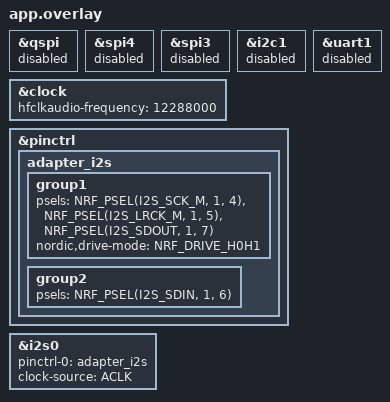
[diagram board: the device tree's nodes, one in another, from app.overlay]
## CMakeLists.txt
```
cmake_minimum_required(VERSION 3.20.0)
find_package(Zephyr REQUIRED HINTS $ENV{ZEPHYR_BASE})
project(openearable_adapter)
target_include_directories(app PRIVATE ../../common src)
target_sources(app PRIVATE src/main.c src/link.c src/pcm.c src/earables.c)
# Build-local hook: do not block Bluetooth RX while awaiting the earable's ATT reply.
set(ATT_SOURCE ${ZEPHYR_BASE}/subsys/bluetooth/host/att.c)
set(ATT_PROXY_SOURCE ${CMAKE_CURRENT_BINARY_DIR}/adapter_att.c)
add_custom_command(OUTPUT ${ATT_PROXY_SOURCE}
    COMMAND ${PYTHON_EXECUTABLE} ${CMAKE_CURRENT_SOURCE_DIR}/cmake/att_hook.py
        ${ATT_SOURCE} ${ATT_PROXY_SOURCE}
    DEPENDS ${ATT_SOURCE} ${CMAKE_CURRENT_SOURCE_DIR}/cmake/att_hook.py
    VERBATIM)
add_custom_target(adapter_att_hook DEPENDS ${ATT_PROXY_SOURCE})
add_dependencies(subsys__bluetooth__host adapter_att_hook)
get_target_property(HOST_SOURCES subsys__bluetooth__host SOURCES)
list(FILTER HOST_SOURCES EXCLUDE REGEX "(^|/)att\\.c$")
set_property(TARGET subsys__bluetooth__host PROPERTY SOURCES ${HOST_SOURCES} ${ATT_PROXY_SOURCE})
target_include_directories(subsys__bluetooth__host PRIVATE ${ZEPHYR_BASE}/subsys/bluetooth/host)
target_sources(app PRIVATE src/proxy.c)
```

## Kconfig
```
# SPDX-License-Identifier: Apache-2.0
mainmenu "OpenEarable adapter"

config ADAPTER_SDC_ISO_CLOCK
    bool
    default y
    select BT_LL_SOFTDEVICE_HEADERS_INCLUDE
    help
      The network core runs SoftDevice Controller. Use its HCI timestamp
      command to align stereo SDUs even though the host runs on the app core.

source "Kconfig.zephyr"
```

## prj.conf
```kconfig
CONFIG_GPIO=y
CONFIG_ADC=y
CONFIG_PINCTRL=y
CONFIG_I2S=y
CONFIG_NRFX_SPIS3=y
CONFIG_FPU=y
CONFIG_FPU_SHARING=y
CONFIG_LIBLC3=y
CONFIG_SPEED_OPTIMIZATIONS=y
CONFIG_MAIN_STACK_SIZE=4096
CONFIG_SYSTEM_WORKQUEUE_STACK_SIZE=4096
CONFIG_HEAP_MEM_POOL_SIZE=32768
# Match Nordic's unicast-client crypto heap: 512 bytes can exhaust during
# CSIP SIRK decryption while another link is pairing or reconnecting.
CONFIG_MBEDTLS_HEAP_SIZE=2048
CONFIG_BT=y
CONFIG_BT_CENTRAL=y
CONFIG_BT_PERIPHERAL=y
CONFIG_BT_MAX_CONN=4
CONFIG_BT_MAX_PAIRED=8
CONFIG_BT_SMP=y
CONFIG_BT_BONDABLE=y
CONFIG_BT_SETTINGS=y
CONFIG_BT_DEVICE_NAME="OpenEarable Adapter"
CONFIG_BT_DEVICE_NAME_DYNAMIC=y
CONFIG_BT_DEVICE_NAME_MAX=64
CONFIG_BT_ID_MAX=3
CONFIG_BT_EXT_ADV=y
CONFIG_BT_EXT_ADV_MAX_ADV_SET=2
CONFIG_BT_GATT_CLIENT=y
CONFIG_BT_GATT_DYNAMIC_DB=y
CONFIG_BT_GATT_AUTO_DISCOVER_CCC=y
# Mirrored CCCs are checked by the proxy for its per-ear host connection.
CONFIG_BT_GATT_ENFORCE_SUBSCRIPTION=n
CONFIG_BT_GATT_AUTO_UPDATE_MTU=y
CONFIG_BT_USER_PHY_UPDATE=y
CONFIG_BT_AUTO_PHY_UPDATE=y
CONFIG_BT_USER_DATA_LEN_UPDATE=y
CONFIG_BT_AUTO_DATA_LEN_UPDATE=y
CONFIG_BT_ATT_TX_COUNT=12
CONFIG_BT_L2CAP_TX_BUF_COUNT=16
CONFIG_BT_CONN_TX_MAX=12
CONFIG_BT_BUF_ACL_TX_COUNT=12
CONFIG_BT_BUF_ACL_RX_COUNT_EXTRA=8
CONFIG_BT_L2CAP_TX_MTU=247
CONFIG_BT_BUF_ACL_RX_SIZE=251
CONFIG_BT_BUF_ACL_TX_SIZE=251
CONFIG_BT_BUF_EVT_RX_SIZE=255
CONFIG_BT_BUF_CMD_TX_SIZE=255
CONFIG_BT_AUDIO=y
CONFIG_BT_ISO_CENTRAL=y
CONFIG_BT_BAP_UNICAST_CLIENT=y
CONFIG_BT_CSIP_SET_COORDINATOR=y
CONFIG_BT_BAP_UNICAST_CLIENT_GROUP_STREAM_COUNT=2
CONFIG_BT_BAP_UNICAST_CLIENT_ASE_SNK_COUNT=2
CONFIG_BT_BAP_UNICAST_CLIENT_ASE_SRC_COUNT=2
CONFIG_BT_ISO_MAX_CHAN=2
CONFIG_BT_ISO_TX_BUF_COUNT=8
CONFIG_BT_ISO_RX_BUF_COUNT=8
CONFIG_BT_ISO_TX_MTU=155
CONFIG_BT_ISO_RX_MTU=155
CONFIG_SETTINGS=y
CONFIG_FLASH=y
CONFIG_FLASH_MAP=y
CONFIG_NVS=y
CONFIG_SETTINGS_NVS=y
CONFIG_LOG=y
CONFIG_LOG_MODE_DEFERRED=y
CONFIG_LOG_BUFFER_SIZE=8192
CONFIG_LOG_BACKEND_UART=n
CONFIG_LOG_BACKEND_RTT=y
CONFIG_USE_SEGGER_RTT=y
CONFIG_RTT_CONSOLE=y
CONFIG_UART_CONSOLE=n
CONFIG_CONSOLE=y
CONFIG_SEGGER_RTT_BUFFER_SIZE_UP=8192
CONFIG_SEGGER_RTT_BUFFER_SIZE_DOWN=256
CONFIG_ASSERT=y
CONFIG_NRF_APPROTECT_USE_UICR=y
```

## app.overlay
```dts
#include <zephyr/dt-bindings/pinctrl/nrf-pinctrl.h>
&qspi { status = "disabled"; };
&spi4 { status = "disabled"; };
&spi3 { status = "disabled"; };
&i2c1 { status = "disabled"; };
&uart1 { status = "disabled"; };
&clock { hfclkaudio-frequency = <12288000>; };
&pinctrl {
    adapter_i2s: adapter_i2s {
        group1 {
            psels = <NRF_PSEL(I2S_SCK_M, 1, 4)>,
                    <NRF_PSEL(I2S_LRCK_M, 1, 5)>,
                    <NRF_PSEL(I2S_SDOUT, 1, 7)>;
            nordic,drive-mode = <NRF_DRIVE_H0H1>;
        };
        group2 {
            psels = <NRF_PSEL(I2S_SDIN, 1, 6)>;
        };
    };
};
&i2s0 {
    status = "okay";
    pinctrl-0 = <&adapter_i2s>;
    pinctrl-names = "default";
    clock-source = "ACLK";
};
```

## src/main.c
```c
/* SPDX-License-Identifier: Apache-2.0 */
#include "adapter.h"
#include <zephyr/drivers/gpio.h>
#include <SEGGER_RTT.h>
#include <zephyr/random/random.h>
#include <hal/nrf_clock.h>
#include <nrfx_clock.h>
atomic_t host_flags, ear_flags, link_errors, pcm_frames, pcm_peak, pairing_token, test_mode,
    reset_epoch;
uint32_t boot_id;
K_MUTEX_DEFINE(name_mutex);
char pair_name[64] = "OpenEarable Adapter";
char pair_hardware_revision[16];
static const struct device *gpio0 = DEVICE_DT_GET(DT_NODELABEL(gpio0));
void adapter_led(unsigned index, bool on) { gpio_pin_set(gpio0, 28 + index, !on); }
int main(void) {
    /* Four LC3 operations per 10 ms frame need the full application CPU clock. */
    nrfx_err_t clock_error = nrfx_clock_divider_set(NRF_CLOCK_DOMAIN_HFCLK, NRF_CLOCK_HFCLK_DIV_1);
    if (clock_error != NRFX_SUCCESS) {
        printk("CPU clock error=%u\n", clock_error);
        return -EIO;
    }
    for (unsigned i = 0; i < 4; i++)
        gpio_pin_configure(gpio0, 28 + i, GPIO_OUTPUT_HIGH);
    gpio_pin_configure(gpio0, 23, GPIO_INPUT | GPIO_PULL_UP);
    gpio_pin_configure(gpio0, 24, GPIO_INPUT | GPIO_PULL_UP);
    printk("OpenEarable adapter boot\n");
    boot_id = sys_rand32_get();
    earables_init();
    /* Load the saved reset epoch before publishing any SPI status. Otherwise
     * the ESP sees a transient zero at boot and clears its host bonds. */
    link_init();
    printk("PCM init=%d\n", pcm_init());
    int64_t combo = 0;
    bool combo_fired = false;
    int64_t pressed[2] = {0};
    bool fired[2] = {0};
    char line[80];
    unsigned used = 0;
    int64_t report = 0;
    for (;;) {
        int64_t now = k_uptime_get();
        bool both = gpio_pin_get(gpio0, 23) == 0 && gpio_pin_get(gpio0, 24) == 0;
        if (both) {
            if (!combo)
                combo = now;
            if (!combo_fired && now - combo >= 10000) {
                combo_fired = true;
                earables_reset();
            }
        } else {
            combo = 0;
            combo_fired = false;
        }
        for (unsigned i = 0; i < 2; i++) {
            if (both) {
                pressed[i] = 0;
                fired[i] = true;
                continue;
            }
            if (gpio_pin_get(gpio0, 23 + i) == 0) {
                if (!pressed[i])
                    pressed[i] = now;
                if (!fired[i] && now - pressed[i] >= 5000) {
                    fired[i] = true;
                    if (i == 0)
                        earables_pair();
                    else
                        atomic_inc(&pairing_token);
                }
            } else {
                /* A short press retries the saved set, for example when its
                 * second member has just been switched back on. */
                if (i == 0 && pressed[i] && !fired[i] && now - pressed[i] >= 50 &&
                    now - pressed[i] < 1000)
                    earables_resume();
                pressed[i] = 0;
                fired[i] = false;
            }
        }
        char c;
        while (SEGGER_RTT_Read(0, &c, 1)) {
            if (c == '\n' || c == '\r') {
                line[used] = 0;
                if (!strcmp(line, "PAIR"))
                    earables_pair();
                else if (!strcmp(line, "RESET"))
                    earables_reset();
                else if (!strcmp(line, "SUSPEND"))
                    earables_suspend();
                else if (!strcmp(line, "RECONNECT"))
                    earables_resume();
                else if (!strcmp(line, "RADIO"))
                    earables_radio_status();
                else if (!strcmp(line, "HOSTPAIR"))
                    atomic_inc(&pairing_token);
                else if (!strcmp(line, "TEST ON"))
                    atomic_set(&test_mode, 1);
                else if (!strcmp(line, "TEST OFF"))
                    atomic_set(&test_mode, 0);
                else if (!strcmp(line, "CLOCK"))
                    printk("CLOCK base=%p run=%lu stat=%lu freq=%lu\n", NRF_CLOCK,
                           (unsigned long)NRF_CLOCK->HFCLKAUDIORUN,
                           (unsigned long)NRF_CLOCK->HFCLKAUDIOSTAT,
                           (unsigned long)NRF_CLOCK->HFCLKAUDIO.FREQUENCY);
                else if (used)
                    printk("COMMAND unknown %s\n", line);
                used = 0;
            } else if (used < sizeof(line) - 1)
                line[used++] = c;
        }
        adapter_led(0, (now / 1000) % 2);
        adapter_led(1, (atomic_get(&ear_flags) & OE_EAR_PAIRING)
                           ? (now / 200) % 2
                           : (atomic_get(&ear_flags) & OE_EAR_CONNECTED));
        adapter_led(2, (atomic_get(&host_flags) & OE_HOST_PAIRABLE)
                           ? (now / 200) % 2
                           : (atomic_get(&host_flags) & OE_HOST_CONNECTED));
        adapter_led(3, atomic_get(&ear_flags) & OE_EAR_STREAMING);
        if (now - report >= 5000) {
            report = now;
            printk("STATUS frames=%ld peak=%ld errors=%ld host=%ld ear=%ld name=%s\n",
                   (long)atomic_get(&pcm_frames), (long)atomic_get(&pcm_peak),
                   (long)atomic_get(&link_errors), (long)atomic_get(&host_flags),
                   (long)atomic_get(&ear_flags), pair_name);
        }
        k_sleep(K_MSEC(20));
    }
}
```

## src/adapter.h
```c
/* SPDX-License-Identifier: Apache-2.0 */
#pragma once
#include <zephyr/kernel.h>
#include <zephyr/bluetooth/conn.h>
#include <stdint.h>
#include "link.h"
#define PCM_SAMPLES 480
#define PCM_BYTES (PCM_SAMPLES * 2 * sizeof(int16_t))
extern atomic_t host_flags, ear_flags, link_errors, pcm_frames, pcm_peak;
extern atomic_t pairing_token, test_mode, reset_epoch;
extern uint32_t boot_id;
extern struct k_mutex name_mutex;
extern char pair_name[64];
extern char pair_hardware_revision[16];
void link_init(void);
int pcm_init(void);
void earables_init(void);
void earables_pair(void);
void earables_reset(void);
void earables_suspend(void);
void earables_resume(void);
void earables_radio_status(void);
void earables_send(const int16_t *stereo);
void earables_capture(int16_t *stereo);
void adapter_led(unsigned index, bool on);
```

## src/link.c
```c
/* SPDX-License-Identifier: Apache-2.0 */
#include "adapter.h"
#include <nrfx_spis.h>
#include <hal/nrf_gpio.h>
#include <zephyr/irq.h>
static const nrfx_spis_t spis = NRFX_SPIS_INSTANCE(3);
static struct oe_link_frame tx __aligned(4), rx __aligned(4);
static K_SEM_DEFINE(done, 0, 1);
atomic_t spi_length_errors, spi_crc_errors, spi_buffer_errors;
static void event(nrfx_spis_evt_t const *e, void *context) {
    if (e->evt_type == NRFX_SPIS_BUFFERS_SET_DONE)
        nrf_gpio_pin_set(NRF_GPIO_PIN_MAP(1, 11));
    if (e->evt_type == NRFX_SPIS_XFER_DONE) {
        nrf_gpio_pin_clear(NRF_GPIO_PIN_MAP(1, 11));
        if (e->rx_amount != sizeof(rx)) {
            atomic_inc(&spi_length_errors);
            atomic_inc(&link_errors);
        }
        k_sem_give(&done);
    }
}
static void run(void *a, void *b, void *c) {
    uint32_t sequence = 0;
    for (;;) {
        memset(&tx, 0, sizeof(tx));
        tx.sequence = ++sequence;
        tx.pairing_token = atomic_get(&pairing_token);
        tx.pcm_frames = atomic_get(&pcm_frames);
        tx.errors = atomic_get(&link_errors);
        tx.peak = atomic_get(&pcm_peak);
        tx.boot_id = boot_id;
        k_mutex_lock(&name_mutex, K_FOREVER);
        tx.flags = atomic_get(&ear_flags) | (atomic_get(&test_mode) ? OE_LINK_TEST : 0);
        tx.reset_epoch = atomic_get(&reset_epoch);
        memcpy(tx.name, pair_name, sizeof(tx.name));
        memcpy(tx.hardware_revision, pair_hardware_revision, sizeof(tx.hardware_revision));
        k_mutex_unlock(&name_mutex);
        oe_link_seal(&tx);
        int err =
            nrfx_spis_buffers_set(&spis, (uint8_t *)&tx, sizeof(tx), (uint8_t *)&rx, sizeof(rx));
        if (err != NRFX_SUCCESS) {
            atomic_inc(&spi_buffer_errors);
            atomic_inc(&link_errors);
            k_sleep(K_MSEC(20));
            continue;
        }
        // Keep DMA buffers owned by SPIS until completion, but expire stale
        // host state when the ESP resets or stops supplying valid frames.
        while (k_sem_take(&done, K_MSEC(100)))
            atomic_set(&host_flags, 0);
        if (oe_link_valid(&rx))
            atomic_set(&host_flags, rx.flags);
        else {
            atomic_inc(&spi_crc_errors);
            atomic_set(&host_flags, 0);
            atomic_inc(&link_errors);
        }
    }
}
static K_THREAD_STACK_DEFINE(stack, 1536);
static struct k_thread thread;
void link_init(void) {
    nrf_gpio_cfg_output(NRF_GPIO_PIN_MAP(1, 11));
    nrf_gpio_pin_clear(NRF_GPIO_PIN_MAP(1, 11));
    nrfx_spis_config_t cfg =
        NRFX_SPIS_DEFAULT_CONFIG(NRF_GPIO_PIN_MAP(1, 15), NRF_GPIO_PIN_MAP(1, 13),
                                 NRF_GPIO_PIN_MAP(1, 14), NRF_GPIO_PIN_MAP(1, 12));
    cfg.mode = NRF_SPIS_MODE_0;
    cfg.bit_order = NRF_SPIS_BIT_ORDER_MSB_FIRST;
    IRQ_CONNECT(NRFX_IRQ_NUMBER_GET(NRF_SPIS3), 4, nrfx_spis_3_irq_handler, 0, 0);
    int err = nrfx_spis_init(&spis, &cfg, event, NULL);
    printk("LINK init=%d size=%u\n", err, (unsigned)sizeof(tx));
    if (err == NRFX_SUCCESS)
        k_thread_create(&thread, stack, K_THREAD_STACK_SIZEOF(stack), run, NULL, NULL, NULL, 5, 0,
                        K_NO_WAIT);
}
```

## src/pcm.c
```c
/* SPDX-License-Identifier: Apache-2.0 */
#include "adapter.h"
#include <zephyr/drivers/i2s.h>
#include <stdlib.h>
#include <hal/nrf_clock.h>
static const struct device *dev = DEVICE_DT_GET(DT_NODELABEL(i2s0));
#define WIRE_BYTES (PCM_SAMPLES * 2 * sizeof(int32_t))
K_MEM_SLAB_DEFINE_STATIC(rx_slab, WIRE_BYTES, 8, 4);
K_MEM_SLAB_DEFINE_STATIC(tx_slab, WIRE_BYTES, 8, 4);
static int16_t input[PCM_SAMPLES * 2];
static int16_t output[PCM_SAMPLES * 2];
/* Debugger-readable 100 ms capture; 1=request, 2=capturing, 3=complete. */
atomic_t pcm_snapshot_state;
atomic_t pcm_recoveries, pcm_process_max_us;
atomic_t pcm_padding_errors;
/* Diagnostic fault injection is only armed explicitly on the adapter debugger. */
atomic_t pcm_inject_delay_ms;
int16_t mic_snapshot[PCM_SAMPLES * 2 * 10];
int16_t pcm_snapshot[PCM_SAMPLES * 2 * 10];
static int start(void) {
    for (unsigned i = 0; i < 3; i++) {
        void *block;
        int err = k_mem_slab_alloc(&tx_slab, &block, K_NO_WAIT);
        if (err)
            return err;
        memset(block, 0, WIRE_BYTES);
        err = i2s_write(dev, block, WIRE_BYTES);
        if (err) {
            k_mem_slab_free(&tx_slab, block);
            return err;
        }
    }
    return i2s_trigger(dev, I2S_DIR_BOTH, I2S_TRIGGER_START);
}
static void recover(void) {
    /* ERROR has already stopped and uninitialized nrfx I2S in its IRQ.
     * DROP calls nrfx_i2s_stop() again and asserts on that uninitialized
     * instance (NCS 3.0.1). PREPARE is the documented ERROR -> READY path.
     * Let the asynchronous STOPPED callback finish before reinitializing. */
    atomic_inc(&pcm_recoveries);
    k_sleep(K_MSEC(20));
    int err = i2s_trigger(dev, I2S_DIR_BOTH, I2S_TRIGGER_PREPARE);
    if (!err)
        err = start();
    printk("PCM recovery=%d\n", err);
    if (err)
        k_sleep(K_MSEC(100));
}
static void run(void *a, void *b, void *c) {
    uint32_t phase = 0;
    unsigned snapshot_block = 0;
    for (;;) {
        int delay = atomic_set(&pcm_inject_delay_ms, 0);
        if (delay > 0 && delay <= 200)
            k_sleep(K_MSEC(delay));
        void *block;
        size_t size;
        int err = i2s_read(dev, &block, &size);
        if (err) {
            recover();
            continue;
        }
        uint32_t begin = k_cycle_get_32();
        /* Use 32-bit slots with zero padding after the 16-bit PCM sample.
         * The ESP32 slave otherwise corrupts the next slot at a word boundary. */
        int32_t *wire = block;
        for (unsigned i = 0; i < ARRAY_SIZE(input); i++) {
            if (i < size / sizeof(*wire) && (wire[i] & 0xffff))
                atomic_inc(&pcm_padding_errors);
            input[i] = i < size / sizeof(*wire) ? wire[i] >> 16 : 0;
        }
        k_mem_slab_free(&rx_slab, block);
        if (!(atomic_get(&host_flags) & (OE_HOST_PLAYING | OE_HOST_MIC_ACTIVE)))
            memset(input, 0, sizeof(input));
        if (atomic_get(&pcm_snapshot_state) == 1) {
            snapshot_block = 0;
            atomic_set(&pcm_snapshot_state, 2);
        }
        if (atomic_get(&pcm_snapshot_state) == 2) {
            memcpy(pcm_snapshot + snapshot_block * PCM_SAMPLES * 2, input, sizeof(input));
            /* Mark complete only after recording the corresponding return block. */
        }
        int peak = 0;
        for (int i = 0; i < PCM_SAMPLES * 2; i++)
            peak = MAX(peak, abs(input[i]));
        atomic_set(&pcm_peak, peak);
        atomic_inc(&pcm_frames);
        earables_send(input);
        if (k_mem_slab_alloc(&tx_slab, &block, K_MSEC(20)))
            continue;
        earables_capture(output);
        if (atomic_get(&pcm_snapshot_state) == 2) {
            memcpy(mic_snapshot + snapshot_block * PCM_SAMPLES * 2, output, sizeof(output));
            if (++snapshot_block == 10)
                atomic_set(&pcm_snapshot_state, 3);
        }
        if (atomic_get(&test_mode)) {
            int16_t *out = output;
            /* Digital fixture only: low-level 1 kHz square wave on the return wire. */
            for (int i = 0; i < PCM_SAMPLES; i++, phase++)
                out[2 * i] = out[2 * i + 1] = (phase % 48 < 24) ? 1000 : -1000;
        }
        wire = block;
        for (unsigned i = 0; i < ARRAY_SIZE(output); i++)
            wire[i] = (int32_t)output[i] * 65536;
        err = i2s_write(dev, block, WIRE_BYTES);
        if (err) {
            k_mem_slab_free(&tx_slab, block);
            recover();
        }
        uint32_t elapsed = k_cyc_to_us_floor32(k_cycle_get_32() - begin);
        if (elapsed > atomic_get(&pcm_process_max_us))
            atomic_set(&pcm_process_max_us, elapsed);
    }
}
static K_THREAD_STACK_DEFINE(stack, 8192);
static struct k_thread thread;
int pcm_init(void) {
    if (!device_is_ready(dev))
        return -ENODEV;
    /* Selecting ACLK did not start the audio PLL on the tested DK. Its
     * unstarted clock ran about 0.5% fast and ignored frequency adjustment.
     * Start it explicitly and verify its state before any I2S transfer. */
    nrf_clock_task_trigger(NRF_CLOCK, NRF_CLOCK_TASK_HFCLKAUDIOSTART);
    int64_t deadline = k_uptime_get() + 100;
    while (!(NRF_CLOCK->HFCLKAUDIOSTAT & CLOCK_HFCLKAUDIOSTAT_STATE_Msk)) {
        if (k_uptime_get() >= deadline)
            return -ETIMEDOUT;
        k_sleep(K_MSEC(1));
    }
    struct i2s_config cfg = {.word_size = 32,
                             .channels = 2,
                             .format = I2S_FMT_DATA_FORMAT_I2S,
                             .options = I2S_OPT_BIT_CLK_MASTER | I2S_OPT_FRAME_CLK_MASTER,
                             .frame_clk_freq = 48000,
                             .block_size = WIRE_BYTES,
                             .timeout = 2000,
                             .mem_slab = &rx_slab};
    int err = i2s_configure(dev, I2S_DIR_RX, &cfg);
    if (err)
        return err;
    cfg.mem_slab = &tx_slab;
    err = i2s_configure(dev, I2S_DIR_TX, &cfg);
    if (err)
        return err;
    err = start();
    if (err)
        return err;
    k_thread_create(&thread, stack, K_THREAD_STACK_SIZEOF(stack), run, NULL, NULL, NULL, 3, 0,
                    K_NO_WAIT);
    return 0;
}
```

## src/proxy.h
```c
/* SPDX-License-Identifier: Apache-2.0 */
#pragma once
#include <zephyr/bluetooth/conn.h>
#include <stddef.h>
#include <zephyr/bluetooth/uuid.h>
void proxy_init(void);
int proxy_attach(unsigned peer, struct bt_conn *conn, char *name, size_t size);
void proxy_discard_pending(unsigned peer);
int proxy_advertise(unsigned peers);
void proxy_reset(void);
int proxy_read_uuid(struct bt_conn *conn, const struct bt_uuid *uuid, void *data, size_t size);
int proxy_set_render_volume(unsigned peer, struct bt_conn *conn, uint8_t volume);
```
